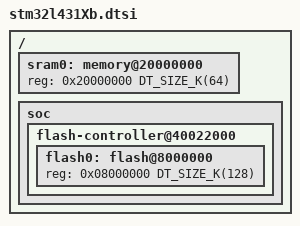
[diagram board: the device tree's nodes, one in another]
/*
 * Copyright (c) 2025 Mirai SHINJO
 * Copyright (c) 2025 Alexander Apostolu
 *
 * SPDX-License-Identifier: Apache-2.0
 */

#include <st/l4/stm32l431.dtsi>

/ {
	sram0: memory@20000000 {
		reg = <0x20000000 DT_SIZE_K(64)>;
	};

	soc {
		flash-controller@40022000 {
			flash0: flash@8000000 {
				reg = <0x08000000 DT_SIZE_K(128)>;
			};
		};
	};
};
